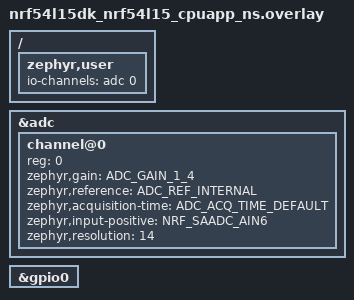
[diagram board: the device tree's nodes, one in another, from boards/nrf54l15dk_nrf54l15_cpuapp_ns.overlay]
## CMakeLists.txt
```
# SPDX-License-Identifier: Apache-2.0

cmake_minimum_required(VERSION 3.20.0)

find_package(Zephyr REQUIRED HINTS $ENV{ZEPHYR_BASE})
project(synchronization)

include_directories(src/)

target_sources(app PRIVATE src/main.c)
target_sources(app PRIVATE src/water_valves.c)
```

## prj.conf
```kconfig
#
# Copyright (c) 2024 Nordic Semiconductor
#
# SPDX-License-Identifier: LicenseRef-Nordic-5-Clause
#

CONFIG_LOG=y
# STEP 1 - Enable the ADC API and driver
CONFIG_ADC=y

# 
CONFIG_STDOUT_CONSOLE=y

# enable to use thread names
CONFIG_THREAD_NAME=y
CONFIG_SCHED_CPU_MASK=y

CONFIG_GPIO=y
CONFIG_LOG=y

# Enable debugging
CONFIG_DEBUG_THREAD_INFO=y
CONFIG_DEBUG_OPTIMIZATIONS=y

#
CONFIG_STDOUT_CONSOLE=y

# NEWLIB C
CONFIG_NEWLIB_LIBC=y
CONFIG_NEWLIB_LIBC_FLOAT_PRINTF=y

# enable to use thread names
CONFIG_THREAD_NAME=y
CONFIG_SCHED_CPU_MASK=y

# 
CONFIG_NRFX_TIMER00=y
CONFIG_NRFX_TIMER10=y
CONFIG_NRFX_TIMER20=y
CONFIG_NRFX_TIMER21=y

#CONFIG_NRFX_TIMER22=y
#CONFIG_NRFX_TIMER23=y
#CONFIG_NRFX_TIMER24=y

# 
CONFIG_NRFX_SYSTICK=y

# Enable nrfx SAADC driver
CONFIG_NRFX_SAADC=y

# 
CONFIG_BT=y
CONFIG_BT_PERIPHERAL=y
CONFIG_BT_ZEPHYR_NUS=y
#CONFIG_BT_DEVICE_NAME="A Smart Solar Powered Water Tank"

# 
CONFIG_NFCT_PINS_AS_GPIOS=y 
 
 
```

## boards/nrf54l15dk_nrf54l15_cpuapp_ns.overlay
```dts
/*
 * SPDX-License-Identifier: Apache-2.0
 *
 * Copyright (c) 2022 Nordic Semiconductor ASA
 */


/ {
	zephyr,user {
		io-channels = <&adc 0>;
	};
};

&adc {
	#address-cells = <1>;
	#size-cells = <0>;
	status = "okay";
	channel@0 {
		reg = <0>;
		zephyr,gain = "ADC_GAIN_1_4";
		zephyr,reference = "ADC_REF_INTERNAL";
		zephyr,acquisition-time = <ADC_ACQ_TIME_DEFAULT>;
		zephyr,input-positive = <NRF_SAADC_AIN6>; /* P1.11 for the nRF54L15 DK */
		zephyr,resolution = <14>;
	};
};


&gpio0 {
	//status = "disabled";
	status = "okay";
};
```

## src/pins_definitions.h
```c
/********************************************************************************/
//  
 
 
// 
/* P0 signal */ 					/* Function */	   /* Peripheral */  /* Default connected on P0  */
/* PORT P0 */	
#define PORT_P0_PIN00 				0 // ( UART0_TXD ) |                 |        Yes 
#define PORT_P0_PIN01				1 // ( UART0_RXD ) |                 |        Yes 
#define PORT_P0_PIN02				2 // ( UART0_RST ) |                 |        Yes 
#define PORT_P0_PIN03				3 // ( UART0_CST ) |                 |        Yes 
#define PORT_P0_PIN04				4 // ( BUTTON 3 )  |   Button 3      |        Yes 


/* P0 signal */ 					/* Function */		 	/* Peripheral */ 	/* Default connected on P1  */
/* PORT P1  */
#define PORT_P1_PIN00 				0 // ( 32.768 kHz, XL1 ) |                    |     No, solder bridges must be configured     
#define PORT_P1_PIN01				1 // ( 32.768 kHz, XL2 ) |                    |     No, solder bridges must be configured      
#define PORT_P1_PIN02				2 // ( NFC1 )            |                    |     No, 0R resistors must be configured  
#define PORT_P1_PIN03				3 // ( NFC2 )            |                    |     No, 0R resistors must be configured  
#define PORT_P1_PIN04 				4 // ( UART1_TXD )  AIN0 |                    |     Yes 
#define PORT_P1_PIN05				5 // ( UART1_RXD )  AIN1 |                    |     Yes  
#define PORT_P1_PIN06				6 // ( UART1_RST )  AIN2 |                    |     Yes  
#define PORT_P1_PIN07				7 // ( UART1_CTS )  AIN3 |                    |     Yes  
#define PORT_P1_PIN08 				8 // ( BUTTON 2 )        |    Button 2        |     Yes  
#define PORT_P1_PIN09				9 // ( BUTTON 1 )        |    Button 1        |     Yes  
#define PORT_P1_PIN10				10 // ( LED 1 )          |    LED 1           |     Yes
#define PORT_P1_PIN11				11 // ( )           AIN4 |                    |     Yes  
#define PORT_P1_PIN12				12 // ( )           AIN5 |                    |     Yes   
#define PORT_P1_PIN13				13 // ( BUTTON 0 )  AIN6 |    Button 0        |     Yes  
#define PORT_P1_PIN14				14 // ( LED 3 )     AIN7 |    LED 3           |     Yes  


/* GPIO */							/* Flash memory pin */	/* Solder bridge for memory use (default:shorted) */ /* Solder bridge for GPIO use (default: open) */
/* P2 signal */  					/* Function */			/* Peripheral */	/* Default connected on P2 */
/* PORT P2 */	
#define PORT_P2_PIN00 				0 // ( SIO_3/HOLD )   |           SB16         |         SB17
#define PORT_P2_PIN01				1 // ( CLK )          |           SB12         |         SB18
#define PORT_P2_PIN02				2 // ( SIO_0/SI )     |           SB13         |         SB19  
#define PORT_P2_PIN03				3 // ( SIO_2/WP )     |           SB15         |         SB20     
#define PORT_P2_PIN04 				4 // ( SIO_1/SO )     |           SB14         |         SB21    
#define PORT_P2_PIN05				5 // ( CS )           |           SB11         |         SB22
#define PORT_P2_PIN06				6 // ( Trace CLK)     |                        |     Yes  
#define PORT_P2_PIN07				7 // ( Trace [0] )    |   LED 2                |     Yes  
#define PORT_P2_PIN08 				8 // ( Trace [1] )    |                        |     Yes  
#define PORT_P2_PIN09				9 // ( Trace [2] )    |   LED 0                |     Yes  
#define PORT_P2_PIN10				10 // ( Trace [3] )   |                        |     Yes  

/********************************************************************************/
// 

// user leds 
#define LED_ONE	 	 				PORT_P2_PIN09 //  
#define LED_TWO 					PORT_P1_PIN10 //  
#define LED_THREE	  	  	  		PORT_P2_PIN07 // 
#define LED_FOUR 			 		PORT_P1_PIN14 // 
// user buttons
#define USER_BUTTON_ONE		 		PORT_P1_PIN13 // 
#define USER_BUTTON_TWO		 		PORT_P1_PIN09 //  
#define USER_BUTTON_THREE		 	PORT_P1_PIN08 //  
#define USER_BUTTON_FOUR		 	PORT_P0_PIN04 // 

/********************************************************************************/
//  
 

// get ultrasonic range sensor
#define O_ECHO_ULTRASONIC_SENSOR 	PORT_P1_PIN11 // Output pin
#define O_TRIG_ULTRASONIC_SENSOR 	PORT_P2_PIN01 // Input pin

// get ultrasonic range sensor
#define W_ECHO_ULTRASONIC_SENSOR 	PORT_P1_PIN08 // Output pin ( BUTTON 2 )
#define W_TRIG_ULTRASONIC_SENSOR 	PORT_P1_PIN09 // Input pin ( BUTTON 1 ) 
    
// buzzer
#define BUZZER						PORT_P2_PIN00 // 
// pir sensor
#define	PIR_MODULE_PIN				PORT_P1_PIN12 //   
// water valves
#define WATER_VALVE_IN				PORT_P2_PIN02 // water valve in
#define WATER_VALVE_OUT				PORT_P2_PIN03 // water valve out
// water flow sensor
#define WATER_FLOW_SENSOR			PORT_P2_PIN04 //  
// water level sensor
//#define WATER_LEVEL_SENSOR			PORT_P2_PIN05 //
   
// oled display pins
//#define OLED_I2C_SCL  				PORT_P1_PIN02 // OLED_I2C_SCL 
//#define OLED_I2C_SDL  				PORT_P1_PIN03 // OLED_I2C_SDL    
  
// oled display pins
#define OLED_I2C_SCL  				PORT_P2_PIN06 // ( Trace CLK)   
#define OLED_I2C_SDL  				PORT_P2_PIN08 // ( Trace [1] )
  
//#define PORT_P0_PIN04 // ( BUTTON 3 )  
//#define PORT_P1_PIN08 // ( BUTTON 2 )
//#define PORT_P1_PIN09 // ( BUTTON 1 ) 
#define WATER_LEVEL_SENSOR			PORT_P1_PIN13 // ( BUTTON 0 )  AIN6 

/********************************************************************************/
//  

#define SAADC_CHANNEL_0  			0 // 	 
#define SAADC_CHANNEL_1  			1 // 	 
#define SAADC_CHANNEL_2  			2 // 	 
#define SAADC_CHANNEL_3  			3 // 	 
#define SAADC_CHANNEL_4  			4 // 	 
#define SAADC_CHANNEL_5  			5 // 	 
#define SAADC_CHANNEL_6  			6 // 	 
#define SAADC_CHANNEL_7  			7 // 	 

/********************************************************************************/
//  
 

#define SENSORS_STATUS_LED	    	LED_ONE   // 
#define BAT_STATUS_LED          	LED_TWO   // 
#define USER_LED					LED_THREE // 
#define PIR_MODULE_LED              LED_FOUR //   

/********************************************************************************/
//  
 

#define RED_LED	    	            LED_ONE   // 
#define YELLOW_LED          	    LED_TWO   // 
#define GREEN_LED				    LED_THREE // 
#define BLUE_LED                	LED_FOUR //   
  
/********************************************************************************/
//  
 
#define ON 							false
#define OFF							true
 
#define NOT_WATER_FLOWING 			false
#define WATER_FLOWING				true
 
//water_tank_status 
#define WATER_TANK_EMPTY 			false
#define WATER_TANK_FULL				true
// 
/********************************************************************************/ 
```

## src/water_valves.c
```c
/********************************************************************************
 * Copyright (c) 2012-2014 Wind River Systems, Inc.
 *
 * SPDX-License-Identifier: Apache-2.0
 ********************************************************************************/
#include <zephyr/kernel.h>
#include <zephyr/sys/printk.h>
#include <zephyr/drivers/pwm.h>
#include <zephyr/device.h>
#include <zephyr/devicetree.h>
#include <zephyr/drivers/gpio.h>
#include <zephyr/logging/log.h>
#include <stdio.h>
#include "water_valves.h"
#include "pins_definitions.h"

/********************************************************************************
 * 
 ********************************************************************************/
#define WV_DEVICE_GPIO0 DT_NODELABEL(gpio0)
#define WV_DEVICE_GPIO1 DT_NODELABEL(gpio1)
#define WV_DEVICE_GPIO2 DT_NODELABEL(gpio2)

/********************************************************************************
 * 
 ********************************************************************************/
// 
const struct device *wv_gpio0_dev = DEVICE_DT_GET(WV_DEVICE_GPIO0);
// 
const struct device *wv_gpio1_dev = DEVICE_DT_GET(WV_DEVICE_GPIO1);
// 
const struct device *wv_gpio2_dev = DEVICE_DT_GET(WV_DEVICE_GPIO2);

/********************************************************************************
 * @} water_valves_init
 ********************************************************************************/
void water_valves_init(void) 
{
	// set up water_valves pins 
	gpio_pin_configure(wv_gpio2_dev, WATER_VALVE_IN, GPIO_OUTPUT_HIGH);	
	//gpio_pin_set(wv_gpio2_dev, WATER_VALVE_IN, true);
	// set up water_valves pins 
	gpio_pin_configure(wv_gpio2_dev, WATER_VALVE_OUT, GPIO_OUTPUT_HIGH);	
	//gpio_pin_set(wv_gpio2_dev, WATER_VALVE_OUT, true);

}

/********************************************************************************
 * @} water_valves_test
 ********************************************************************************/
void water_valves_test(uint32_t msleepTime, uint32_t valvesOnCount) 
{
	uint32_t i;
	
	for(i = 0; i < valvesOnCount; i++) 
	{
		gpio_pin_set(wv_gpio2_dev, WATER_VALVE_IN, false);
		gpio_pin_set(wv_gpio2_dev, WATER_VALVE_OUT, false);
		k_msleep(msleepTime);
		gpio_pin_set(wv_gpio2_dev, WATER_VALVE_IN, true);
		gpio_pin_set(wv_gpio2_dev, WATER_VALVE_OUT, true);
		k_msleep(msleepTime);
	}
}

/********************************************************************************
 * @} water_valve_in
 ********************************************************************************/
void water_valve_in(bool WaterValveInCount) 
{
	if(WaterValveInCount == ON) 
	{
		gpio_pin_set(wv_gpio2_dev, WATER_VALVE_IN, false);
		gpio_pin_set(wv_gpio2_dev, GREEN_LED, true);
	}
	else 	
	{
		gpio_pin_set(wv_gpio2_dev, WATER_VALVE_IN, true);
		gpio_pin_set(wv_gpio2_dev, GREEN_LED, false);
	}
}

/********************************************************************************
 * @} water_valve_out
 ********************************************************************************/
void water_valve_out(bool WaterValveOutCount) 
{
	if(WaterValveOutCount == ON) 
	{
		gpio_pin_set(wv_gpio2_dev, WATER_VALVE_OUT, false);
	}
	else 	
	{
		gpio_pin_set(wv_gpio2_dev, WATER_VALVE_OUT, true);
	}
}

	
```

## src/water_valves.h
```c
/********************************************************************************
 * Copyright (c) 2012-2014 Wind River Systems, Inc.
 *
 * SPDX-License-Identifier: Apache-2.0
 ********************************************************************************/
#ifndef WATER_VALVES_H 
#define WATER_VALVES_H

#ifdef __cplusplus
extern "C" {
#endif


#define SLEEP_TIME_MS 					1000


#define WATER_VALVE_IN_ON_SLEEP_TIME	100
#define WATER_VALVE_IN_OFF_SLEEP_TIME	50
#define WATER_VALVE_OUT_ON_SLEEP_TIME	100
#define WATER_VALVE_OUT_OFF_SLEEP_TIME	50


void water_valves_init(void);
void water_valves_test(uint32_t msleepTime, uint32_t valvesOnCount); 
void water_valve_in(bool WaterValveInCount);
void water_valve_out(bool WaterValveInCount);

#ifdef __cplusplus
}
#endif

#endif

/********************************************************************************
 * 
 ********************************************************************************/
```
